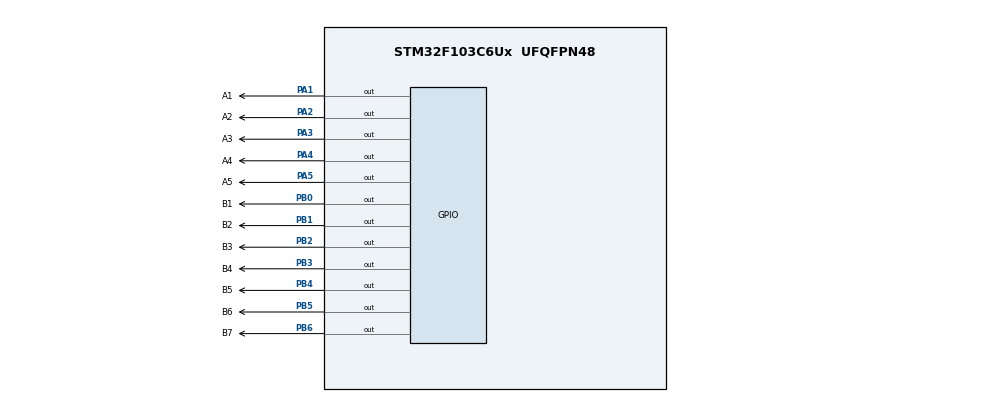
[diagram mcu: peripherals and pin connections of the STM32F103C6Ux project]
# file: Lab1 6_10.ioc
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Mcu.Family=STM32F1
Mcu.Name=STM32F103C6Ux
Mcu.Package=UFQFPN48
NVIC.PriorityGroup=NVIC_PRIORITYGROUP_4
PA1.GPIO_Label=A1
PA1.Signal=GPIO_Output
PA2.GPIO_Label=A2
PA2.Signal=GPIO_Output
PA3.GPIO_Label=A3
PA3.Signal=GPIO_Output
PA4.GPIO_Label=A4
PA4.Signal=GPIO_Output
PA5.GPIO_Label=A5
PA5.Signal=GPIO_Output
PB0.GPIO_Label=B1
PB0.Signal=GPIO_Output
PB1.GPIO_Label=B2
PB1.Signal=GPIO_Output
PB2.GPIO_Label=B3
PB2.Signal=GPIO_Output
PB3.GPIO_Label=B4
PB3.Signal=GPIO_Output
PB4.GPIO_Label=B5
PB4.Signal=GPIO_Output
PB5.GPIO_Label=B6
PB5.Signal=GPIO_Output
PB6.GPIO_Label=B7
PB6.Signal=GPIO_Output
ProjectManager.HeapSize=0x200
ProjectManager.StackSize=0x400
ProjectManager.TargetToolchain=STM32CubeIDE
RCC.APB1Freq_Value=8000000
RCC.APB2Freq_Value=8000000
VP_SYS_VS_ND.Mode=No_Debug
board=custom

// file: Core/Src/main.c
/* USER CODE BEGIN Header */
/**
  ******************************************************************************
  * @file           : main.c
  * @brief          : Main program body
  ******************************************************************************
  * @attention
  *
  * <h2><center>&copy; Copyright (c) 2022 STMicroelectronics.
  * All rights reserved.</center></h2>
  *
  * This software component is licensed by ST under BSD 3-Clause license,
  * the "License"; You may not use this file except in compliance with the
  * License. You may obtain a copy of the License at:
  *                        opensource.org/licenses/BSD-3-Clause
  *
  ******************************************************************************
  */
/* USER CODE END Header */
#include "main.h"

void SystemClock_Config(void);
static void MX_GPIO_Init(void);

int main(void)
{

  /* MCU Configuration--------------------------------------------------------*/

  /* Reset of all peripherals, Initializes the Flash interface and the Systick. */
  HAL_Init();

  /* Configure the system clock */
  SystemClock_Config();

  /* Initialize all configured peripherals */
  MX_GPIO_Init();
  /* USER CODE BEGIN 2 */
  /* // for exercise 10
    int hour = 7;
    int min = 58;
    int sec = 50;

    // LED 0, 3, 6, 9: hour
    // LED 1, 4, 7, 10: min
    // LED 2, 5, 8, 11: sec
    int hour_idx = 0;
    int min_idx = 1;
    int sec_idx = 2; */
  /* USER CODE END 2 */

  /* Infinite loop */
  while (1)
  {

    /* USER CODE BEGIN 3 */

	   /* 	 // exercise 6
	  	  setAllClock(); */

	    /*	 // exercise 7
	  	  setAllClock();
	  	  clearAllClock();
	  	  HAL_Delay(500); */

	   	 /* // exercise 8
	  		  for (int i = 0; i < 12; i++){
	  		  	setNumberOnClock(i);
	  		  	 HAL_Delay(500);
	  		  } */

	  	 /*  // exercise 9
	  	  setNumberOnClock(0);
	  	  HAL_Delay(500);
	  	  clearNumberOnClock(0);
	  	  HAL_Delay(500); */

	    /* // exercise 10

	  	  sec++;
	  	  // update idx
	  	  sec_idx = sec_idx + 3;
	  	  if (sec_idx > 11)
	  		  sec_idx = 2;

	  	  if (sec >= 60) {
	  		  sec = 0;
	  		  min++;
	  		  // update idx
	  		  min_idx = min_idx + 3;
	  		  if (min_idx > 10)
	  			  min_idx = 1;
	  	  }
	  	  if (min >= 60){
	  		  min = 0;
	  		  hour++;
	  		  // update idx
	  		  hour_idx = hour_idx + 3;
	  		  if (hour_idx > 9)
	  			  hour_idx = 0;
	  	  }
	  	  if (hour >= 24){
	  		  hour = 0;
	  	  }

	  	  // display
	  	  setNumberOnClock(hour_idx);
	  	  HAL_Delay(20);
	  	  setNumberOnClock(min_idx);
	  	  HAL_Delay(20);
	  	  setNumberOnClock(sec_idx);
	  	  HAL_Delay(20); */
  }
  /* USER CODE END 3 */
}

void SystemClock_Config(void)
{
  RCC_OscInitTypeDef RCC_OscInitStruct = {0};
  RCC_ClkInitTypeDef RCC_ClkInitStruct = {0};

  /** Initializes the RCC Oscillators according to the specified parameters
  * in the RCC_OscInitTypeDef structure.
  */
  RCC_OscInitStruct.OscillatorType = RCC_OSCILLATORTYPE_HSI;
  RCC_OscInitStruct.HSIState = RCC_HSI_ON;
  RCC_OscInitStruct.HSICalibrationValue = RCC_HSICALIBRATION_DEFAULT;
  RCC_OscInitStruct.PLL.PLLState = RCC_PLL_NONE;
  if (HAL_RCC_OscConfig(&RCC_OscInitStruct) != HAL_OK)
  {
    Error_Handler();
  }
  /** Initializes the CPU, AHB and APB buses clocks
  */
  RCC_ClkInitStruct.ClockType = RCC_CLOCKTYPE_HCLK|RCC_CLOCKTYPE_SYSCLK
                              |RCC_CLOCKTYPE_PCLK1|RCC_CLOCKTYPE_PCLK2;
  RCC_ClkInitStruct.SYSCLKSource = RCC_SYSCLKSOURCE_HSI;
  RCC_ClkInitStruct.AHBCLKDivider = RCC_SYSCLK_DIV1;
  RCC_ClkInitStruct.APB1CLKDivider = RCC_HCLK_DIV1;
  RCC_ClkInitStruct.APB2CLKDivider = RCC_HCLK_DIV1;

  if (HAL_RCC_ClockConfig(&RCC_ClkInitStruct, FLASH_LATENCY_0) != HAL_OK)
  {
    Error_Handler();
  }
}

static void MX_GPIO_Init(void)
{
  GPIO_InitTypeDef GPIO_InitStruct = {0};

  /* GPIO Ports Clock Enable */
  __HAL_RCC_GPIOA_CLK_ENABLE();
  __HAL_RCC_GPIOB_CLK_ENABLE();

  /*Configure GPIO pin Output Level */
  HAL_GPIO_WritePin(GPIOA, A1_Pin|A2_Pin|A3_Pin|A4_Pin
                          |A5_Pin, GPIO_PIN_RESET);

  /*Configure GPIO pin Output Level */
  HAL_GPIO_WritePin(GPIOB, B1_Pin|B2_Pin|B3_Pin|B4_Pin
                          |B5_Pin|B6_Pin|B7_Pin, GPIO_PIN_RESET);

  /*Configure GPIO pins : A1_Pin A2_Pin A3_Pin A4_Pin
                           A5_Pin */
  GPIO_InitStruct.Pin = A1_Pin|A2_Pin|A3_Pin|A4_Pin
                          |A5_Pin;
  GPIO_InitStruct.Mode = GPIO_MODE_OUTPUT_PP;
  GPIO_InitStruct.Pull = GPIO_NOPULL;
  GPIO_InitStruct.Speed = GPIO_SPEED_FREQ_LOW;
  HAL_GPIO_Init(GPIOA, &GPIO_InitStruct);

  /*Configure GPIO pins : B1_Pin B2_Pin B3_Pin B4_Pin
                           B5_Pin B6_Pin B7_Pin */
  GPIO_InitStruct.Pin = B1_Pin|B2_Pin|B3_Pin|B4_Pin
                          |B5_Pin|B6_Pin|B7_Pin;
  GPIO_InitStruct.Mode = GPIO_MODE_OUTPUT_PP;
  GPIO_InitStruct.Pull = GPIO_NOPULL;
  GPIO_InitStruct.Speed = GPIO_SPEED_FREQ_LOW;
  HAL_GPIO_Init(GPIOB, &GPIO_InitStruct);

}

void Error_Handler(void)
{
  __disable_irq();
  while (1)
  {
  }
}

/************************ (C) COPYRIGHT STMicroelectronics *****END OF FILE****/
